VERSION "honda_civic_bosch_radar -- 36802-TBA Bosch FINE per-track object table (0x280 block). Hand-written (NOT generated; named without _generated so it is git-tracked and loaded via the file fallback, like acura_ilx_2016_nidec.dbc). FINE decode cross-car CONFIRMED 2026-06-07 (3 cars / 6 routes; 8905 cross-car tracks fused leadOne.dRel at R^2=0.975 -- radar-re/finerange-confirm/CONFIRM-REPORT.md). This SUPERSEDES the coarse 0x2C8/0x2C9 selected-lead as the RANGE source: range is now carried in B2:B3 of the b1==0x74 header frame of each 4-frame track record at a PHYSICALLY CALIBRATED scale (0.00357 m/unit, offset -3.0). 0x2C8/0x2C9 remain declared below ONLY as a dormant coarse reference; the parser does NOT read range from them. PHYSICAL BUS = openpilot CanBus.camera (rlog src=2), NOT CanBus.radar -- the Bus.radar key is only the DBC-name lookup. The frame counter is carried as CNTR (NOT COUNTER) and there is NO CHECKSUM signal on the fine frames -- opendbc auto-enforces the hardcoded Honda checksum/counter on honda_* DBCs and would DROP every frame on the exact names CHECKSUM/COUNTER; this radar's framing is its own and this is RX-only lead data, so we name around the trap and decode unconditionally."

NS_ :

BS_:

BU_: RADAR XXX

BO_ 640 RADAR_TRACK_0: 8 RADAR
 SG_ STRENGTH : 7|8@0+ (1,0) [0|255] "" XXX
 SG_ TRACK_TAG : 15|8@0+ (1,0) [0|255] "" XXX
 SG_ RANGE : 23|16@0+ (0.00357,-3) [-3|230] "m" XXX
 SG_ RANGE_RAW : 23|16@0+ (1,0) [0|65535] "" XXX
 SG_ LAT_RAW : 39|16@0+ (1,-32768) [-32768|32767] "" XXX
 SG_ CNTR : 63|8@0+ (1,0) [0|255] "" XXX

BO_ 644 RADAR_TRACK_1: 8 RADAR
 SG_ STRENGTH : 7|8@0+ (1,0) [0|255] "" XXX
 SG_ TRACK_TAG : 15|8@0+ (1,0) [0|255] "" XXX
 SG_ RANGE : 23|16@0+ (0.00357,-3) [-3|230] "m" XXX
 SG_ RANGE_RAW : 23|16@0+ (1,0) [0|65535] "" XXX
 SG_ LAT_RAW : 39|16@0+ (1,-32768) [-32768|32767] "" XXX
 SG_ CNTR : 63|8@0+ (1,0) [0|255] "" XXX

BO_ 648 RADAR_TRACK_2: 8 RADAR
 SG_ STRENGTH : 7|8@0+ (1,0) [0|255] "" XXX
 SG_ TRACK_TAG : 15|8@0+ (1,0) [0|255] "" XXX
 SG_ RANGE : 23|16@0+ (0.00357,-3) [-3|230] "m" XXX
 SG_ RANGE_RAW : 23|16@0+ (1,0) [0|65535] "" XXX
 SG_ LAT_RAW : 39|16@0+ (1,-32768) [-32768|32767] "" XXX
 SG_ CNTR : 63|8@0+ (1,0) [0|255] "" XXX

BO_ 652 RADAR_TRACK_3: 8 RADAR
 SG_ STRENGTH : 7|8@0+ (1,0) [0|255] "" XXX
 SG_ TRACK_TAG : 15|8@0+ (1,0) [0|255] "" XXX
 SG_ RANGE : 23|16@0+ (0.00357,-3) [-3|230] "m" XXX
 SG_ RANGE_RAW : 23|16@0+ (1,0) [0|65535] "" XXX
 SG_ LAT_RAW : 39|16@0+ (1,-32768) [-32768|32767] "" XXX
 SG_ CNTR : 63|8@0+ (1,0) [0|255] "" XXX

BO_ 720 RADAR_TRACK_4: 8 RADAR
 SG_ STRENGTH : 7|8@0+ (1,0) [0|255] "" XXX
 SG_ TRACK_TAG : 15|8@0+ (1,0) [0|255] "" XXX
 SG_ RANGE : 23|16@0+ (0.00357,-3) [-3|230] "m" XXX
 SG_ RANGE_RAW : 23|16@0+ (1,0) [0|65535] "" XXX
 SG_ LAT_RAW : 39|16@0+ (1,-32768) [-32768|32767] "" XXX
 SG_ CNTR : 63|8@0+ (1,0) [0|255] "" XXX

BO_ 724 RADAR_TRACK_5: 8 RADAR
 SG_ STRENGTH : 7|8@0+ (1,0) [0|255] "" XXX
 SG_ TRACK_TAG : 15|8@0+ (1,0) [0|255] "" XXX
 SG_ RANGE : 23|16@0+ (0.00357,-3) [-3|230] "m" XXX
 SG_ RANGE_RAW : 23|16@0+ (1,0) [0|65535] "" XXX
 SG_ LAT_RAW : 39|16@0+ (1,-32768) [-32768|32767] "" XXX
 SG_ CNTR : 63|8@0+ (1,0) [0|255] "" XXX

BO_ 728 RADAR_TRACK_6: 8 RADAR
 SG_ STRENGTH : 7|8@0+ (1,0) [0|255] "" XXX
 SG_ TRACK_TAG : 15|8@0+ (1,0) [0|255] "" XXX
 SG_ RANGE : 23|16@0+ (0.00357,-3) [-3|230] "m" XXX
 SG_ RANGE_RAW : 23|16@0+ (1,0) [0|65535] "" XXX
 SG_ LAT_RAW : 39|16@0+ (1,-32768) [-32768|32767] "" XXX
 SG_ CNTR : 63|8@0+ (1,0) [0|255] "" XXX

BO_ 732 RADAR_TRACK_7: 8 RADAR
 SG_ STRENGTH : 7|8@0+ (1,0) [0|255] "" XXX
 SG_ TRACK_TAG : 15|8@0+ (1,0) [0|255] "" XXX
 SG_ RANGE : 23|16@0+ (0.00357,-3) [-3|230] "m" XXX
 SG_ RANGE_RAW : 23|16@0+ (1,0) [0|65535] "" XXX
 SG_ LAT_RAW : 39|16@0+ (1,-32768) [-32768|32767] "" XXX
 SG_ CNTR : 63|8@0+ (1,0) [0|255] "" XXX

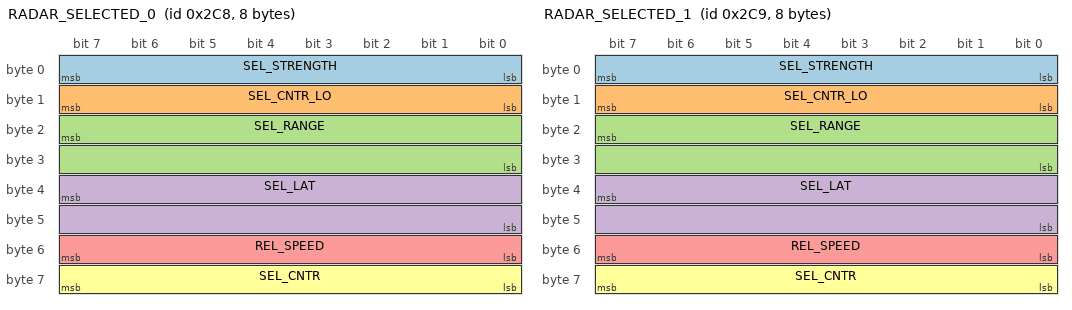
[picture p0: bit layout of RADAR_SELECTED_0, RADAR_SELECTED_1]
BO_ 712 RADAR_SELECTED_0: 8 RADAR
 SG_ SEL_STRENGTH : 7|8@0+ (1,0) [0|255] "" XXX
 SG_ SEL_CNTR_LO : 15|8@0+ (1,0) [0|255] "" XXX
 SG_ SEL_RANGE : 23|16@0+ (1,0) [0|65535] "" XXX
 SG_ SEL_LAT : 39|16@0+ (1,-32768) [-32768|32767] "" XXX
 SG_ REL_SPEED : 55|8@0+ (-0.7,86.5) [-92|87] "m/s" XXX
 SG_ SEL_CNTR : 63|8@0+ (1,0) [0|255] "" XXX

BO_ 713 RADAR_SELECTED_1: 8 RADAR
 SG_ SEL_STRENGTH : 7|8@0+ (1,0) [0|255] "" XXX
 SG_ SEL_CNTR_LO : 15|8@0+ (1,0) [0|255] "" XXX
 SG_ SEL_RANGE : 23|16@0+ (1,0) [0|65535] "" XXX
 SG_ SEL_LAT : 39|16@0+ (1,-32768) [-32768|32767] "" XXX
 SG_ REL_SPEED : 55|8@0+ (-0.7,86.5) [-92|87] "m/s" XXX
 SG_ SEL_CNTR : 63|8@0+ (1,0) [0|255] "" XXX

BO_ 641 RADAR_TRACK_0_SUB1: 8 RADAR
 SG_ AMPLITUDE : 23|16@0+ (1,0) [0|65535] "" XXX
 SG_ SUB_CNTR : 63|8@0+ (1,0) [0|255] "" XXX

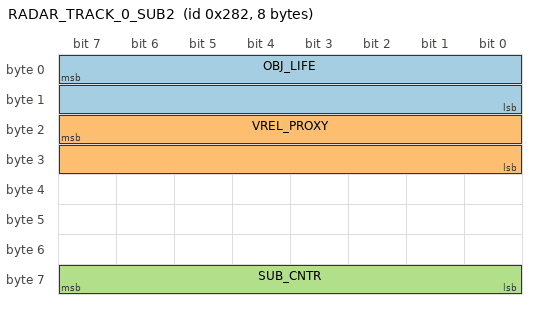
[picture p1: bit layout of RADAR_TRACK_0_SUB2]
BO_ 642 RADAR_TRACK_0_SUB2: 8 RADAR
 SG_ OBJ_LIFE : 7|16@0+ (1,0) [0|65535] "" XXX
 SG_ VREL_PROXY : 23|16@0+ (1,0) [0|65535] "" XXX
 SG_ SUB_CNTR : 63|8@0+ (1,0) [0|255] "" XXX

BO_ 646 RADAR_TRACK_1_SUB2: 8 RADAR
 SG_ OBJ_LIFE : 7|16@0+ (1,0) [0|65535] "" XXX

BO_ 650 RADAR_TRACK_2_SUB2: 8 RADAR
 SG_ OBJ_LIFE : 7|16@0+ (1,0) [0|65535] "" XXX

BO_ 654 RADAR_TRACK_3_SUB2: 8 RADAR
 SG_ OBJ_LIFE : 7|16@0+ (1,0) [0|65535] "" XXX

BO_ 722 RADAR_TRACK_4_SUB2: 8 RADAR
 SG_ OBJ_LIFE : 7|16@0+ (1,0) [0|65535] "" XXX

BO_ 726 RADAR_TRACK_5_SUB2: 8 RADAR
 SG_ OBJ_LIFE : 7|16@0+ (1,0) [0|65535] "" XXX

BO_ 730 RADAR_TRACK_6_SUB2: 8 RADAR
 SG_ OBJ_LIFE : 7|16@0+ (1,0) [0|65535] "" XXX

BO_ 734 RADAR_TRACK_7_SUB2: 8 RADAR
 SG_ OBJ_LIFE : 7|16@0+ (1,0) [0|65535] "" XXX

CM_ "Stock 36802-TBA Bosch radar FINE per-track object table. Big-endian (Motorola), all frames DLC8. The radar broadcasts up to 8 track records, each a 4-frame burst on consecutive IDs; only the HEADER ID of each record (0x280/0x284/0x288/0x28C/0x2D0/0x2D4/0x2D8/0x2DC, a near group 0x280-0x28C + a far group 0x2D0-0x2DC) carries RANGE, and only on the sub-frame where B1 in {0x74 moving, 0x94 stationary} (the range-carrier header tags). The other 3 sub-frames of each record (0x281-0x283, 0x285-0x287, 0x2D1-0x2D3, ...) carry lateral/velocity/status and would decode to spurious sub-zero range -- they are NOT read as range by the parser. NOTE 2026-07-01: slot 0's sub-frames 0x281/0x282 are now DECLARED (RADAR_TRACK_0_SUB1/SUB2) as RX-only REFERENCE signals (AMPLITUDE, VREL_PROXY) documenting a data-mining pass -- they are still NOT parsed into lead points; see their BO_ comments. 0x281.B2:B3 AMPLITUDE is a clean inverse-range return strength (r=-0.76 vs range) usable as a soft real-vs-clutter weight; 0x282.B2:B3 VREL_PROXY correlates -0.63 with the track's own range-rate but is NOT cleanly calibrated (redundant with the parser's KF-derived vRel). NOTE 2026-07-01: slots 0x288/0x28C were previously undeclared (a 6-slot list) and are actually the busiest MID-range slots (~62 m); the old list instead polled the near-dead far slots. Reading all 8 is the correct full-table decode -- but an offline replay of both phantom-fix drives showed it is NEUTRAL for the 40-70 m follow-too-far/false-closing symptom (only ~8% of the added points are the lead; that symptom is a radard fusion issue -- see tmp_radar/RADARD_HANDOFF.md and the BO_ 648 comment). The parser GATES on TRACK_TAG(B1) in {0x74,0x94}. Sentinels (any one -> not an active track): STRENGTH(B0)==0xFE (idle), RANGE_RAW(B2:B3)==0x8000 (~114m unset), RANGE_RAW>=0xFF80 (~230m saturation rail). RANGE and RANGE_RAW intentionally overlap B2:B3 (scaled meters vs raw int for the sentinel test) -- opendbc decodes overlapping signals independently. RANGE scale/offset (0.00357, -3.0) is cross-car-validated; the offset -3.0 is tape-anchored. LAT_RAW is offset-binary (raw 0x8000 = center, declared with offset -32768); its physical m/LSB is NOT pinned, so the parser applies a clearly-placeholdered LAT_SCALE and yRel magnitude is DO_NOT_TRUST until a controlled lateral cal. vRel is NOT published by the radar on the FINE 0x280 frames; the parser derives it as d(dRel)/dt per track. 0x2C8/0x2C9 (RADAR_SELECTED) remain declared as a coarse, RX-only reference and are NOT read by the fine parser; their byte layout was RE-DERIVED 2026-06-30 against the clean vision lead (see BO_ 712 comment) -- the prior LONG_DIST@B0:B1 / REL_SPEED@(0.25,-31.25) layout was WRONG. REL_SPEED is the byte-6 coarse relative velocity, now CALIBRATED (vRel = -0.7*(B6-124) m/s, r=0.90 vs vision).";
CM_ BO_ 640 "Track slot 0 header (record 0x280-0x283). Range carrier when TRACK_TAG(B1) in {0x74 moving, 0x94 stationary}. Head of the 8-slot sweep burst.";
CM_ BO_ 644 "Track slot 1 header (record 0x284-0x287).";
CM_ BO_ 648 "Track slot 2 header (record 0x288-0x28B). Mid-range near-group slot (valid ~30% of sweeps, median range ~62 m). ADDED 2026-07-01: the old 6-slot parser SKIPPED this while polling the near-dead far slots 0x2D4/0x2D8/0x2DC (valid 1%/0%/0%). Reading it is the correct full-table decode; VALIDATION (tmp_radar/validate_replay.py on drives 00000002/00000003) found it NEUTRAL for the 40-70 m follow-too-far symptom -- ~92% of these points are OTHER objects, not the lead, so lead coverage was unchanged. The follow-too-far/false-closing is a radard fusion issue (closer near-slot object vs vision lead), NOT this. Evidence: tmp_radar/slot_map.py, RADARD_HANDOFF.md.";
CM_ BO_ 652 "Track slot 3 header (record 0x28C-0x28F). Mid-range near-group slot (valid ~12%, median ~62 m). ADDED 2026-07-01 alongside slot 2 (0x288); see that comment.";
CM_ BO_ 720 "Track slot 4 header (record 0x2D0-0x2D3). Far-group slot (valid ~3%).";
CM_ BO_ 724 "Track slot 5 header (record 0x2D4-0x2D7). Far-group slot (valid ~1%).";
CM_ BO_ 728 "Track slot 6 header (record 0x2D8-0x2DB). Far-group slot (rarely valid).";
CM_ BO_ 732 "Track slot 7 header (record 0x2DC-0x2DF). Sweep terminator; the parser's trigger_msg (S4 sweep-coherent emit). Stays LAST in the sweep so adding slots 2/3 does not disturb trigger coherence.";
CM_ BO_ 641 "RADAR_TRACK_0_SUB1 (0x281): sub-frame 1 of slot 0's 4-frame record. RX-only REFERENCE, NOT parsed into lead points. AMPLITUDE (B2:B3) is a clean inverse-range return strength (mined 2026-07-01, r=-0.76 vs range; range-bin means 10430->1081 over 0-150 m). Range-normalized it is a soft real-vs-clutter weight (bright-for-range tracks ~3x more likely the true lead, AUC 0.60) -- but does NOT separate the closer-clutter that drives false-closing (that clutter is bright too), so it is a soft radard input, not a standalone gate. The same sub-frame layout repeats per slot (0x285, 0x289, ...).";
CM_ BO_ 642 "RADAR_TRACK_0_SUB2 (0x282): sub-frame 2 of slot 0's 4-frame record. OBJ_LIFE (B0:B1) is the radar's per-object identity/lifetime accumulator -- see its SG comment. VREL_PROXY (B2:B3) correlates -0.63 with the track's OWN range-rate (mined 2026-07-01, once track-swap jumps are rejected) but is NOT cleanly calibrated (per-slot scale disagrees ~5x, integral test fails) -- a noisy velocity-correlate, redundant with the parser's KF-derived vRel, kept only as documentation. The same layout repeats per slot (0x286, 0x28A, 0x28E, 0x2D2, 0x2D6, 0x2DA, 0x2DE = each header+2), now all DECLARED (RADAR_TRACK_1..7_SUB2) so the parser's isolated SUB2 parser can read OBJ_LIFE for every slot.";
CM_ SG_ 641 AMPLITUDE "B2:B3 BE16 raw. Inverse-range return strength / RCS-like amplitude (falls monotonically with range). Soft real-vs-clutter weight after range-normalization; reference only.";
CM_ SG_ 642 VREL_PROXY "B2:B3 BE16 raw. Correlates with the track's own range-rate (-0.63) but not a calibrated Doppler; reference only.";
CM_ SG_ 642 OBJ_LIFE "B0:B1 BE16. The radar's own per-object identity / lifetime accumulator. Ticks +33 per sweep for a continuously-tracked object (deterministic internal sub-counter steps of +17 ~6% / +1 ~2%; NEVER decreases for the same object) and carries a near-unique per-object seed so two SIMULTANEOUS objects collide only 0.2% of the time (spread median ~8448 over live slots). It is the radar's internal track id, which the parser's range/azimuth stitch (S7/S7b) only approximates. VALIDATED 2026-07-06 (tmp_radar/id_perobject.py, id_predicate.py; 6 highway/traffic segments): per-object not a global clock (99.8% discrimination), and over a re-slot gap the SAME object's value advances by (now-old) mod 2^16 in [1, 33*n + 6] for n sweeps -- the S8 continuity predicate. Present on EVERY slot's SUB2 (header+2). On an EMPTY/sentinel slot OBJ_LIFE is a high-rail sentinel (~0xFFF0-0xFFFF), so the parser only reads it for slots with a live range-carrier (never gates on the raw value; a real counter can sit in that range just before its 16-bit wrap). RX-only via an ISOLATED parser: a missing SUB2 frame never affects can_valid; the stitch then falls back to pure S7/S7b geometry. The same layout repeats per slot.";
CM_ SG_ 640 STRENGTH "B0 raw, unscaled. Co-varies with range (return strength, not a flag). Used as the idle sentinel (==0xFE -> no track).";
CM_ SG_ 640 TRACK_TAG "B1 raw. The range-carrier header tag. Parser GATES on ==0x74; any other value is a non-range sub-frame mux'd onto this ID -> SKIP (do not read RANGE).";
CM_ SG_ 640 RANGE "B2:B3 BE16 -> meters. range = 0.00357*raw - 3.0. Scale cross-car-validated (corpus median 0.00357, R^2=0.975 vs fused dRel); offset -3.0 tape-anchored. 16-bit int, no float / no SIG_VALTYPE_ -- the parser consumes meters directly.";
CM_ SG_ 640 RANGE_RAW "B2:B3 BE16 raw (factor 1). Overlaps RANGE; used for the scale-invariant sentinel tests (==0x8000 unset, >=0xFF80 saturation).";
CM_ SG_ 640 LAT_RAW "B4:B5 BE offset-binary, raw 0x8000=center encoded as offset -32768. FIELD IDENTITY = AZIMUTH ANGLE (LSB = deg), settled 2026-06-08 by a three-source rlog regression vs the vision-model lead (~20.9k matched frames; azimuth wins every discriminating segment, range-rate falsified) -- NOT range-rate, NOT lateral-metres. The parser computes the lateral projection trigonometrically: yRel = -dRel*sin((b4b5-0x8000)*LAT_SCALE_DEG_PER_LSB*pi/180), left-positive. LAT_RAW stays a RAW signal here (= b4b5-0x8000); the angle->cartesian math lives in radar_interface.py. Scale ~0.001 deg/LSB (rlog band 0.0007-0.001; 0.001462 REJECTED). Absolute boresight zero-offset still unpinned (per-mount bias).";
CM_ SG_ 640 CNTR "B7 rolling counter. Decoded but UNUSED by openpilot and NOT safety-enforced (named CNTR, not COUNTER, to avoid opendbc's honda_* auto-enforcement that would drop frames).";
CM_ BO_ 712 "RADAR_SELECTED_0 (0x2C8): the radar's single SELECTED-lead coarse output. RX-only reference, NOT read by the fine parser (range/lateral come from the 0x280 block). Layout RE-DERIVED 2026-06-30 by binning raw bytes against the clean vision lead (modelV2.leadsV3[0] range + v - carState.vEgo); the prior DBC layout (LONG_DIST@B0:B1 scale 1, REL_SPEED@0.25,-31.25) was UNVALIDATED guesswork and is now known WRONG. Findings: B0(SEL_STRENGTH)=return strength / inverse-range (108 near <5m -> 55 far >70m); B1/B7=rolling counters; B2:B3(SEL_RANGE)=coarse range proxy, raw, scale unvalidated; B4:B5(SEL_LAT)=offset-binary lateral (~center => lead dead-ahead); B6(REL_SPEED)=coarse relative velocity, see SG comment. Most data was vRel in [-1,1] (stop-and-go) so scales are not pinned -- needs a high-Delta-v capture.";
CM_ SG_ 712 REL_SPEED "B6 native relative velocity (Doppler) for the SELECTED lead. CALIBRATED 2026-07-01 against the clean vision lead on two high-Delta-v highway segments (route 00000007--66c6f132c5 seg 6 & 22, single clear lead): vRel = -0.7*B6 + 86.5 m/s (zero at B6~124), r=0.90, RMS 1.32 m/s over vRel -6..+9 m/s. 8-bit only (B6; 16-bit combos add no info) so resolution ~0.7 m/s/LSB (coarse). SIGN: B6 rises as the lead closes. Scale +/-10% (seg fits -0.68..-0.76) and validated only to ~+/-9 m/s so far. The legacy 0.25,-31.25 was WRONG. This is a REAL published Doppler (no derivation lag) but SELECTED-lead only. EXPOSED 2026-07-01: the parser reads this and attaches it to fine SLOT 0's RadarPoint as vRelNative (RX-only, does NOT change vRel/control). Mining (tmp_radar/mine_doppler2.py) showed the selected lead associates to slot 0 (closest track) at r=0.84 vs slot0's own range-rate; the zero (raw ~124) is stable across drives but the SLOPE is coarse/drive-dependent (-0.8 highway / -1.1 night). NOT fused into vRel: a standalone opendbc vRel veto damps 10-26% of REAL closings (unsafe without vision); the fusion is radard-side (RADARD_HANDOFF.md). Association is gated by a calibration-free velocity-agreement check (|REL_SPEED - slot0.vRel| < 8 m/s).";
CM_ SG_ 712 SEL_RANGE "B2:B3 BE16 raw. Coarse range proxy (rises with distance); scale unvalidated and nonlinear at close range. The FINE 0x280 block is the calibrated range source -- this is reference only.";
CM_ SG_ 712 SEL_LAT "B4:B5 BE offset-binary (raw 0x8000=center, offset -32768). Lateral position of the selected lead; ~center in this corpus (lead dead-ahead). Scale unvalidated.";
CM_ SG_ 712 SEL_STRENGTH "B0 return strength / inverse-range proxy (108 near -> 55 far). Not a distance in meters.";
